# CY8C5868AXI_LP035 register map
File version: 0.1
CY8C58LP
Registers are 8-bit, read-write, no defined reset value unless marked. A register's access mark holds for its fields unless they carry their own. Offsets are from the block's base; lines under a group give offsets from that group; [hi:lo] are bit positions; {n}, {i} and the like mark numbered series; 'fields as' and 'values as' point back to an identical list; <NAME> marks a mode.

## Memory map
0x00000000 SPIS_1

## SPIS_1
Base 0x00000000
0x40006407 SPIS_1_TX_DATA — SPIS TX Data
0x40006407 SPIS_1_RX_DATA — SPIS RX Data
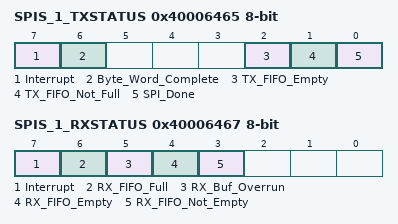
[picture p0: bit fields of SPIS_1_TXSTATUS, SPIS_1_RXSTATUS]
0x40006465 SPIS_1_TXSTATUS — SPIS TX Status Register
  [7] Interrupt ro — Set when interrupt occurs
  [6] Byte_Word_Complete ro — Set when a byte/word transmit has completed
  [2] TX_FIFO_Empty ro — Set when the TX Data FIFO is empty
  [1] TX_FIFO_Not_Full ro — Set when the TX Data FIFO is not full
  [0] SPI_Done ro — Set when all of the data in the transmit FIFO has been sent. Set when Byte/Word Complete has been set and TX Data FIFO is empty
0x40006467 SPIS_1_RXSTATUS — SPIS RX Status Register
  [7] Interrupt ro — Set when interrupt occurs
  [6] RX_FIFO_Full ro — Set when the RX Data FIFO is full
  [5] RX_Buf_Overrun ro — Set when RX Data has overrun the 4 byte/word FIFO without being moved to the RX buffer cmemory array (if one exists)
  [4] RX_FIFO_Empty ro — Set when the RX Data FIFO is empty
  [3] RX_FIFO_Not_Empty ro — Set when the RX Data FIFO is not empty. That is, at least one byte/word is in the RX FIFO
